# STM32F091xC register map
File version: 1.0
Registers are 32-bit, read-write, reset 0x0 unless marked. A register's access mark holds for its fields unless they carry their own. Offsets are from the block's base; [hi:lo] are bit positions; {n}, {i} and the like mark numbered series.

## EXTI — External Interrupt/Event Controller
Base 0x40010400
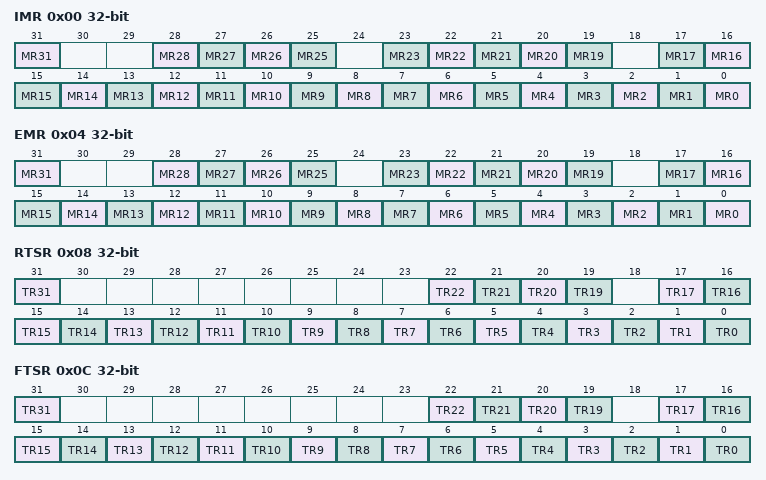
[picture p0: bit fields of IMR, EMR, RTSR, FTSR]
0x00 IMR — EXTI Interrupt mask register
  [31] MR31 — Interrupt Mask on line 31
  [n] MR{n} (n=25..28) — Interrupt Mask on line {n}
  [n] MR{n} (n=19..23) — Interrupt Mask on line {n}
  [n] MR{n} (n=0..17) — Interrupt Mask on line {n}
0x04 EMR — EXTI Event mask register
  [31] MR31 — Event Mask on line 31
  [n] MR{n} (n=25..28) — Event Mask on line {n}
  [n] MR{n} (n=19..23) — Event Mask on line {n}
  [n] MR{n} (n=0..17) — Event Mask on line {n}
0x08 RTSR — EXTI Rising trigger selection register
  [31] TR31 — Rising trigger event configuration bit of line 31
  [n] TR{n} (n=19..22) — Rising trigger event configuration bit of line {n}
  [n] TR{n} (n=0..17) — Rising trigger event configuration bit of line {n}
0x0C FTSR — EXTI Falling trigger selection register
  [31] TR31 — Falling trigger event configuration bit of line 31
  [n] TR{n} (n=19..22) — Falling trigger event configuration bit of line {n}
  [n] TR{n} (n=0..17) — Falling trigger event configuration bit of line {n}
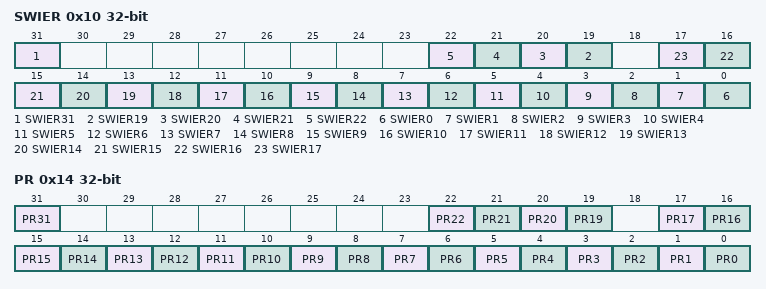
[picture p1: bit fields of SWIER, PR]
0x10 SWIER — EXTI Software interrupt event register
  [31] SWIER31 — Software Interrupt on line 31
  [n] SWIER{n} (n=19..22) — Software Interrupt on line {n}
  [n] SWIER{n} (n=0..17) — Software Interrupt on line {n}
0x14 PR — EXTI Pending register
  [31] PR31 — Pending bit 31
  [n] PR{n} (n=19..22) — Pending bit {n}
  [n] PR{n} (n=0..17) — Pending bit {n}

## ADC
Base 0x40012708
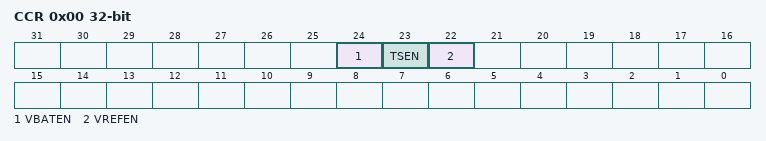
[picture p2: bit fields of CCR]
0x00 CCR — ADC common configuration register
  [24] VBATEN — ADC internal path to battery voltage enable
  [23] TSEN — ADC internal path to temperature sensor enable
  [22] VREFEN — ADC internal path to VrefInt enable

## DBGMCU — Debug MCU
Base 0x40015800
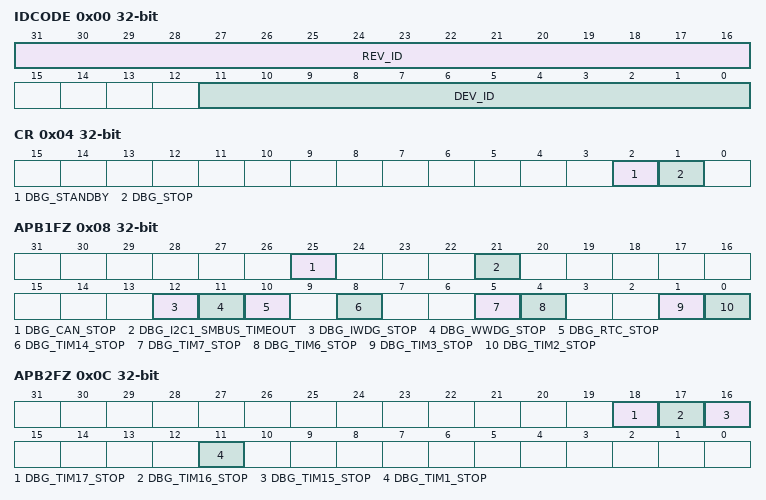
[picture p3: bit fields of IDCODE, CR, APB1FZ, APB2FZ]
0x00 IDCODE — MCU device ID code
  [31:16] REV_ID — REV_ID[15:0] bits (Revision Identifier)
  [11:0] DEV_ID — Device Identifier
0x04 CR — Debug MCU configuration register
  [2] DBG_STANDBY — Debug Standby mode
  [1] DBG_STOP — Debug Stop Mode
0x08 APB1FZ — Debug MCU APB1 freeze register
  [25] DBG_CAN_STOP — CAN debug stopped when Core is halted
  [21] DBG_I2C1_SMBUS_TIMEOUT — I2C1 SMBUS timeout mode stopped when Core is halted
  [12] DBG_IWDG_STOP — Debug Independent Watchdog stopped when Core is halted
  [11] DBG_WWDG_STOP — Debug Window Watchdog stopped when Core is halted
  [10] DBG_RTC_STOP — RTC Calendar frozen when core is halted
  [8] DBG_TIM14_STOP — TIM14 counter stopped when core is halted
  [5] DBG_TIM7_STOP — TIM7 counter stopped when core is halted
  [4] DBG_TIM6_STOP — TIM6 counter stopped when core is halted
  [1] DBG_TIM3_STOP — TIM3 counter stopped when core is halted
  [0] DBG_TIM2_STOP — TIM2 counter stopped when core is halted
0x0C APB2FZ — Debug MCU APB2 freeze register
  [18] DBG_TIM17_STOP — TIM17 counter stopped when core is halted
  [17] DBG_TIM16_STOP — TIM16 counter stopped when core is halted
  [16] DBG_TIM15_STOP — TIM15 counter stopped when core is halted
  [11] DBG_TIM1_STOP — TIM1 counter stopped when core is halted

## FLASH — FLASH Registers
Base 0x40022000
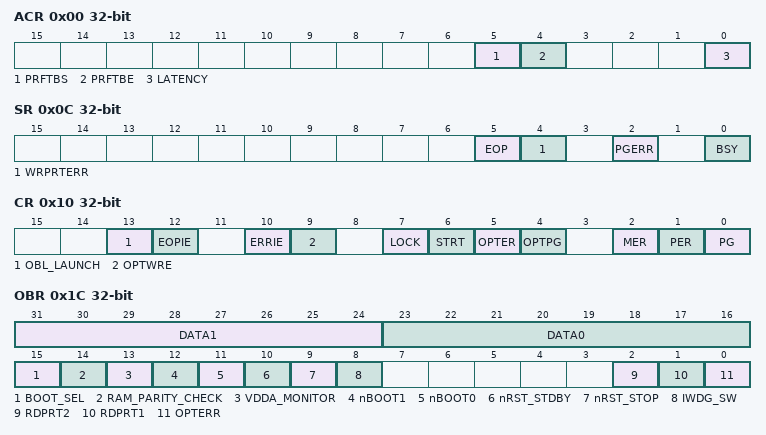
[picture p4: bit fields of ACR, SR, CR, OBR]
0x00 ACR — FLASH access control register
  [5] PRFTBS — Prefetch Buffer Status
  [4] PRFTBE — Prefetch Buffer Enable
  [0] LATENCY — LATENCY bit (Latency)
    0=FLASH Zero Latency cycle; 1=FLASH One Latency cycle
0x04 KEYR — FLASH key register
  [31:0] FKEYR — FPEC Key
0x08 OPTKEYR — FLASH OPT key register
  [31:0] OPTKEYR — Option Byte Key
0x0C SR — FLASH status register
  [5] EOP — End of operation
  [4] WRPRTERR — Write Protection Error
  [2] PGERR — Programming Error
  [0] BSY — Busy
0x10 CR — FLASH control register
  [13] OBL_LAUNCH — Option Bytes Loader Launch
  [12] EOPIE — End of operation interrupt enable
  [10] ERRIE — Error Interrupt Enable
  [9] OPTWRE — Option Bytes Write Enable
  [7] LOCK
  [6] STRT — Start
  [5] OPTER — Option Byte Erase
  [4] OPTPG — Option Byte Programming
  [2] MER — Mass Erase
  [1] PER — Page Erase
  [0] PG — Programming
0x14 AR — FLASH address register
  [31:0] FAR — Flash Address
0x1C OBR — FLASH option bytes register
  [31:24] DATA1
  [23:16] DATA0
  [15] BOOT_SEL — BOOT selection
  [14] RAM_PARITY_CHECK
  [13] VDDA_MONITOR — VDDA power supply supervisor
  [12] nBOOT1
  [11] nBOOT0
  [10] nRST_STDBY
  [9] nRST_STOP
  [8] IWDG_SW
  [2] RDPRT2 — Read protection Level 2
  [1] RDPRT1 — Read protection Level 1
  [0] OPTERR — Option Byte Error
0x20 WRPR — FLASH option bytes register
  [15:0] WRP — Write Protect
